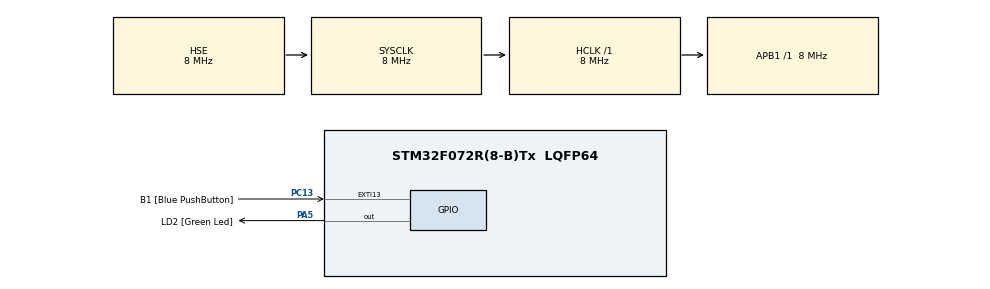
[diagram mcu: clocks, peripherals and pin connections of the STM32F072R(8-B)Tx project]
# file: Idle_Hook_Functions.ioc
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Mcu.Family=STM32F0
Mcu.Name=STM32F072R(8-B)Tx
Mcu.Package=LQFP64
PA13.GPIO_Label=TMS
PA13.Mode=Serial_Wire
PA13.Signal=SYS_SWDIO
PA14.GPIO_Label=TCK
PA14.Mode=Serial_Wire
PA14.Signal=SYS_SWCLK
PA5.GPIO_Label=LD2 [Green Led]
PA5.GPIO_Mode=GPIO_MODE_OUTPUT_PP
PA5.GPIO_PuPd=GPIO_NOPULL
PA5.GPIO_Speed=GPIO_SPEED_FREQ_LOW
PA5.Signal=GPIO_Output
PC13.GPIO_Label=B1 [Blue PushButton]
PC13.GPIO_ModeDefaultEXTI=GPIO_MODE_IT_FALLING
PC13.Signal=GPXTI13
PC14-OSC32_IN.Signal=RCC_OSC32_IN
PC15-OSC32_OUT.Signal=RCC_OSC32_OUT
PF0-OSC_IN.Mode=HSE-External-Oscillator
PF0-OSC_IN.Signal=RCC_OSC_IN
PF1-OSC_OUT.Mode=HSE-External-Oscillator
PF1-OSC_OUT.Signal=RCC_OSC_OUT
ProjectManager.HeapSize=0x200
ProjectManager.StackSize=0x400
ProjectManager.TargetToolchain=STM32CubeIDE
RCC.AHBFreq_Value=8000000
RCC.APB1Freq_Value=8000000
RCC.APB1TimFreq_Value=8000000
RCC.FLatency-AdvancedSettings=FLASH_LATENCY_0
RCC.HCLKFreq_Value=8000000
RCC.PLLDivider=RCC_PREDIV_DIV2
RCC.PLLMUL=RCC_PLL_MUL12
RCC.PREFETCH_ENABLE-AdvancedSettings=1
RCC.SYSCLKFreq_VALUE=8000000
RCC.SYSCLKSource=RCC_SYSCLKSOURCE_HSE
board=NUCLEO-F072RB

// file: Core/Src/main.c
/* USER CODE BEGIN Header */
/**
  ******************************************************************************
  * @file           : main.c
  * @brief          : Main program body
  ******************************************************************************
  * @attention
  *
  * Copyright (c) 2024 STMicroelectronics.
  * All rights reserved.
  *
  * This software is licensed under terms that can be found in the LICENSE file
  * in the root directory of this software component.
  * If no LICENSE file comes with this software, it is provided AS-IS.
  *
  ******************************************************************************
  */
/* USER CODE END Header */
#include "main.h"

/* USER CODE BEGIN Includes */
#include "FreeRTOS.h"
#include "task.h"

/* USER CODE END Includes */

/* USER CODE BEGIN PTD */
TaskHandle_t myTask1Handler = NULL ;
TaskHandle_t myTask2Handler = NULL ;

uint8_t deneme =0 ;

/* USER CODE END PTD */

void SystemClock_Config(void);
static void MX_GPIO_Init(void);

/* USER CODE BEGIN 0 */

void vApplicationIdleHook()
{

	deneme=3;

	__WFI();

	/*
	 * bu arkadaş mcu yu uyutur onun clock sinyallerini uyutur
	 *
	 * bu arkadaş bir interrupt geldiğininde mcu yu uyandırır
	 *
	 * interrpt da bizim hangi görevin vtaskdelay ı dolduysa ben uyandım der ve vtaskscheduler i dürter ben uyandım der
	 *
	 * haliyle bir interrupt oluşur ve bu interrupt sinyali __WFI() ya gider ve mcu ya uyan der
	 *
	 * sonrasonda task1 çalışmaya başlar aynı senaryo döner :)
	 *
	 *
	 *__WFI() fonksiyonu mikrodenetleyiciyi uyutarak enerji tasarrufu yapmamıza yardımcı olur
	 *__WFI() ve bir kesme geldiğinde onu uyandırır.
	 *
	 *
	 *
	 * __WFI(); BU FONKS kullanmadığında nucleo da IDD yerinden akım ölç 10.20mA ile 5.40 mA arasında değer ölçersin
	 * __WFI(); bu fonk kullandığında 7.90 mA ile 3 mA arasında değer alırsın yani daha düşük güç tüketimi olur
	 *
	 *
	 * */

	/*
	 ----------------------------
	      task1|

				.................

	task2|
	 ----------------------------

	 |->(burada vtaskdelay geldi task2 uyudu) ve task1 çalışmaya başladı

	 |-> burada vtaskdelay geldi ve task1 uyudu

	 ... -> bu kısımda bir boşluğun oldu idle task çalışır burada çünkü çalışan görevin yok diğerleri uykuda

	 ... -> #define configUSE_IDLE_HOOK 1 yaptık bundan dolayı hiç bir görev çalışmadığında
	 	 vApplicationIdleHook fonksiyonu çalışacak.

	*/

}

void Task1_Handler(void *params)
{
	deneme = 1;

	while(1)
	{
		HAL_GPIO_TogglePin(GPIOA, GPIO_PIN_5);

		vTaskDelay(pdMS_TO_TICKS(1000));
	}

}

void Task2_Handler(void *params)
{
	deneme = 2 ;

	while(1)
	{
		HAL_GPIO_TogglePin(GPIOA, GPIO_PIN_5);

		vTaskDelay(pdMS_TO_TICKS(1000));

	}

}

/* USER CODE END 0 */

int main(void)
{

  /* MCU Configuration--------------------------------------------------------*/

  /* Reset of all peripherals, Initializes the Flash interface and the Systick. */
  HAL_Init();

  /* Configure the system clock */
  SystemClock_Config();

  /* Initialize all configured peripherals */
  MX_GPIO_Init();
  /* USER CODE BEGIN 2 */

  /*
   *  #define configUSE_IDLE_HOOK 1 yaptık
   	   vApplicationIdleHook fonksiyonunu declaration ettik
   *
   *
   *
   *
   *
   * */

  xTaskCreate(Task1_Handler, "Task_1", 120, NULL, 2, &myTask1Handler);

  xTaskCreate(Task2_Handler, "Task_2", 120, NULL, 2, &myTask2Handler);

  vTaskStartScheduler();

  /* USER CODE END 2 */

  /* Infinite loop */
  while (1)
  {

  }
}

void SystemClock_Config(void)
{
  RCC_OscInitTypeDef RCC_OscInitStruct = {0};
  RCC_ClkInitTypeDef RCC_ClkInitStruct = {0};

  /** Initializes the RCC Oscillators according to the specified parameters
  * in the RCC_OscInitTypeDef structure.
  */
  RCC_OscInitStruct.OscillatorType = RCC_OSCILLATORTYPE_HSE;
  RCC_OscInitStruct.HSEState = RCC_HSE_ON;
  RCC_OscInitStruct.PLL.PLLState = RCC_PLL_NONE;
  if (HAL_RCC_OscConfig(&RCC_OscInitStruct) != HAL_OK)
  {
    Error_Handler();
  }

  /** Initializes the CPU, AHB and APB buses clocks
  */
  RCC_ClkInitStruct.ClockType = RCC_CLOCKTYPE_HCLK|RCC_CLOCKTYPE_SYSCLK
                              |RCC_CLOCKTYPE_PCLK1;
  RCC_ClkInitStruct.SYSCLKSource = RCC_SYSCLKSOURCE_HSE;
  RCC_ClkInitStruct.AHBCLKDivider = RCC_SYSCLK_DIV1;
  RCC_ClkInitStruct.APB1CLKDivider = RCC_HCLK_DIV1;

  if (HAL_RCC_ClockConfig(&RCC_ClkInitStruct, FLASH_LATENCY_0) != HAL_OK)
  {
    Error_Handler();
  }
}

static void MX_GPIO_Init(void)
{
  GPIO_InitTypeDef GPIO_InitStruct = {0};

  /* GPIO Ports Clock Enable */
  __HAL_RCC_GPIOC_CLK_ENABLE();
  __HAL_RCC_GPIOF_CLK_ENABLE();
  __HAL_RCC_GPIOA_CLK_ENABLE();

  /*Configure GPIO pin Output Level */
  HAL_GPIO_WritePin(LD2_GPIO_Port, LD2_Pin, GPIO_PIN_RESET);

  /*Configure GPIO pin : B1_Pin */
  GPIO_InitStruct.Pin = B1_Pin;
  GPIO_InitStruct.Mode = GPIO_MODE_IT_FALLING;
  GPIO_InitStruct.Pull = GPIO_NOPULL;
  HAL_GPIO_Init(B1_GPIO_Port, &GPIO_InitStruct);

  /*Configure GPIO pin : LD2_Pin */
  GPIO_InitStruct.Pin = LD2_Pin;
  GPIO_InitStruct.Mode = GPIO_MODE_OUTPUT_PP;
  GPIO_InitStruct.Pull = GPIO_NOPULL;
  GPIO_InitStruct.Speed = GPIO_SPEED_FREQ_LOW;
  HAL_GPIO_Init(LD2_GPIO_Port, &GPIO_InitStruct);

}

void Error_Handler(void)
{
  __disable_irq();
  while (1)
  {
  }
}
